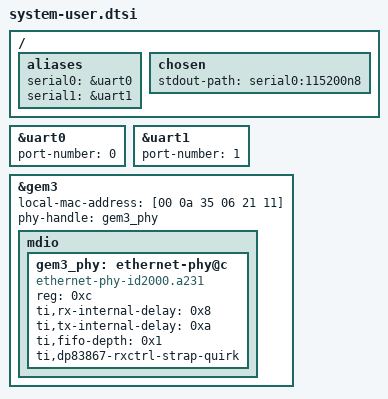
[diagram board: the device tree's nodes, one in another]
// SPDX-License-Identifier: MIT
// Copyright (C) 2025-2026, Opsero Electronic Design Inc.  All rights reserved.

/*
 * SoC-side board fixups, layered on top of the gen-machineconf /
 * lopper-generated cortexa53-linux.dts (which already carries the PS config
 * and the PL xilinx_xdma PCIe node(s) from the XSA).
 *
 * UART (ttyPS console):
 *   The 2025.2 lopper/gen-machineconf flow emits port-number = <0> on BOTH
 *   uart0 (ff000000) and uart1 (ff010000), so the ttyPS0/ttyPS1 assignment is
 *   left to probe order. This board's console is on psu_uart_0, so pin the
 *   port numbers (and serial aliases) explicitly. Mirrors the PetaLinux BSPs.
 *
 * Note: unlike the ZCU104, this board's SD interface sustains UHS modes (the
 * PetaLinux BSP needs no sdhci cap), so no SD override is applied here.
 */

&uart0 {
   port-number = <0>;
};

&uart1 {
   port-number = <1>;
};

/ {
   aliases {
      serial0 = &uart0;
      serial1 = &uart1;
   };
   chosen {
      stdout-path = "serial0:115200n8";
   };
};

/* PS GEM3 (board RJ45): the SDT flow does not describe the board-level
 * TI DP83867 PHY, so Linux falls back to the Generic PHY driver and the
 * RGMII clock delays are never programmed - the link negotiates 1G but
 * passes no packets. Values from the official zynqmp-zcu111-revA.dts
 * (PHY at MDIO address 0xc; its reset-gpios line is omitted because the
 * TCA6416 expander it references is not in the SDT device tree - the
 * PHY powers up out of reset from its straps). The fixed MAC replaces
 * the random one the SDT flow leaves us with, keeping DHCP leases
 * stable across boots.
 */
&gem3 {
	local-mac-address = [00 0a 35 06 21 11];
	phy-handle = <&gem3_phy>;
	mdio {
		#address-cells = <1>;
		#size-cells = <0>;
		gem3_phy: ethernet-phy@c {
			compatible = "ethernet-phy-id2000.a231";
			reg = <0xc>;
			ti,rx-internal-delay = <0x8>;
			ti,tx-internal-delay = <0xa>;
			ti,fifo-depth = <0x1>;
			ti,dp83867-rxctrl-strap-quirk;
		};
	};
};
